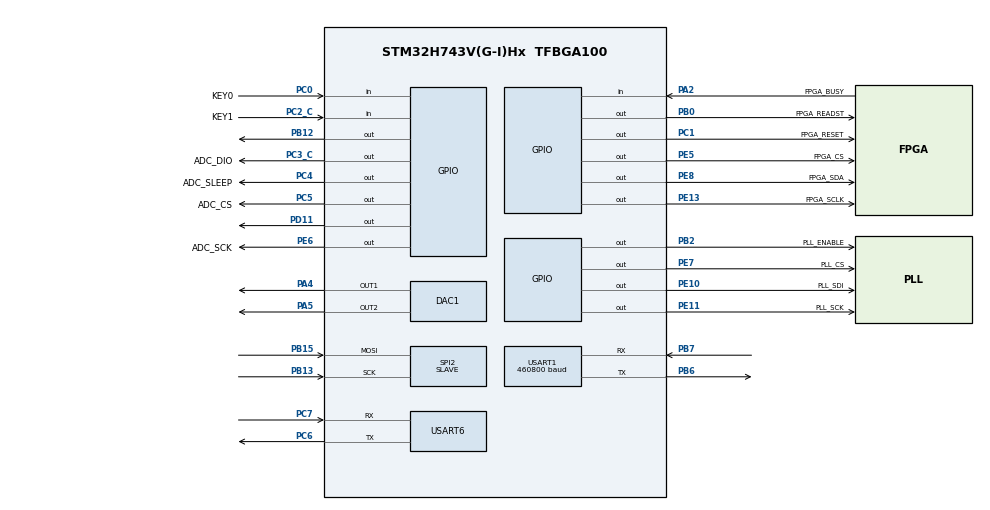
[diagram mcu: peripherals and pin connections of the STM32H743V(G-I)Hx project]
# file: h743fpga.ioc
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CORTEX_M7.CPU_ICache=Enabled
DAC1.DAC_Channel-DAC_OUT1=DAC_CHANNEL_1
DAC1.DAC_Channel-DAC_OUT2=DAC_CHANNEL_2
Dma.Request0=SPI2_RX
Dma.SPI2_RX.0.Direction=DMA_PERIPH_TO_MEMORY
Dma.SPI2_RX.0.EventEnable=DISABLE
Dma.SPI2_RX.0.FIFOMode=DMA_FIFOMODE_DISABLE
Dma.SPI2_RX.0.Instance=DMA1_Stream0
Dma.SPI2_RX.0.MemDataAlignment=DMA_MDATAALIGN_HALFWORD
Dma.SPI2_RX.0.MemInc=DMA_MINC_ENABLE
Dma.SPI2_RX.0.Mode=DMA_CIRCULAR
Dma.SPI2_RX.0.PeriphDataAlignment=DMA_PDATAALIGN_HALFWORD
Dma.SPI2_RX.0.PeriphInc=DMA_PINC_DISABLE
Dma.SPI2_RX.0.Polarity=HAL_DMAMUX_REQ_GEN_RISING
Dma.SPI2_RX.0.Priority=DMA_PRIORITY_LOW
Dma.SPI2_RX.0.RequestNumber=1
Dma.SPI2_RX.0.SignalID=NONE
Dma.SPI2_RX.0.SyncEnable=DISABLE
Dma.SPI2_RX.0.SyncPolarity=HAL_DMAMUX_SYNC_NO_EVENT
Dma.SPI2_RX.0.SyncRequestNumber=1
Dma.SPI2_RX.0.SyncSignalID=NONE
Mcu.Family=STM32H7
Mcu.Name=STM32H743V(G-I)Hx
Mcu.Package=TFBGA100
NVIC.DMA1_Stream0_IRQn=true\:0\:0\:false\:false\:true\:false\:true\:true
NVIC.PriorityGroup=NVIC_PRIORITYGROUP_4
NVIC.SPI2_IRQn=true\:0\:0\:false\:false\:true\:true\:true\:true
NVIC.TIM2_IRQn=true\:0\:0\:false\:false\:true\:true\:true\:true
NVIC.TIM6_DAC_IRQn=true\:0\:0\:false\:false\:true\:true\:true\:true
NVIC.TIM7_IRQn=true\:0\:0\:false\:false\:true\:true\:true\:true
NVIC.USART1_IRQn=true\:0\:0\:false\:false\:true\:true\:true\:true
NVIC.USART6_IRQn=true\:0\:0\:false\:false\:true\:true\:true\:true
PA13\ (JTMS/SWDIO).Mode=JTAG_5_pins
PA13\ (JTMS/SWDIO).Signal=DEBUG_JTMS-SWDIO
PA14\ (JTCK/SWCLK).Mode=JTAG_5_pins
PA14\ (JTCK/SWCLK).Signal=DEBUG_JTCK-SWCLK
PA15\ (JTDI).Mode=JTAG_5_pins
PA15\ (JTDI).Signal=DEBUG_JTDI
PA2.GPIO_Label=FPGA_BUSY
PA2.Signal=GPIO_Input
PA4.Signal=COMP_DAC11_group
PA5.Signal=COMP_DAC12_group
PB0.GPIO_Label=FPGA_READST
PB0.GPIO_Speed=GPIO_SPEED_FREQ_HIGH
PB0.PinState=GPIO_PIN_RESET
PB0.Signal=GPIO_Output
PB12.GPIO_Speed=GPIO_SPEED_FREQ_HIGH
PB12.PinState=GPIO_PIN_SET
PB12.Signal=GPIO_Output
PB13.GPIO_Speed=GPIO_SPEED_FREQ_VERY_HIGH
PB13.Mode=RX_Only_Simplex_Unidirect_Slave
PB13.Signal=SPI2_SCK
PB15.GPIO_Speed=GPIO_SPEED_FREQ_VERY_HIGH
PB15.Mode=RX_Only_Simplex_Unidirect_Slave
PB15.Signal=SPI2_MOSI
PB2.GPIO_Label=PLL_ENABLE
PB2.GPIO_Speed=GPIO_SPEED_FREQ_LOW
PB2.Signal=GPIO_Output
PB3\ (JTDO/TRACESWO).Mode=JTAG_5_pins
PB3\ (JTDO/TRACESWO).Signal=DEBUG_JTDO-SWO
PB4\ (NJTRST).Mode=JTAG_5_pins
PB4\ (NJTRST).Signal=DEBUG_JTRST
PB6.Mode=Asynchronous
PB6.Signal=USART1_TX
PB7.Mode=Asynchronous
PB7.Signal=USART1_RX
PC0.GPIO_Label=KEY0
PC0.Signal=GPIO_Input
PC1.GPIO_Label=FPGA_RESET
PC1.GPIO_Speed=GPIO_SPEED_FREQ_HIGH
PC1.PinState=GPIO_PIN_SET
PC1.Signal=GPIO_Output
PC2_C.GPIO_Label=KEY1
PC2_C.GPIO_PuPd=GPIO_PULLUP
PC2_C.Signal=GPIO_Input
PC3_C.GPIO_Label=ADC_DIO
PC3_C.GPIO_ModeDefaultOutputPP=GPIO_MODE_OUTPUT_PP
PC3_C.GPIO_PuPd=GPIO_PULLUP
PC3_C.GPIO_Speed=GPIO_SPEED_FREQ_LOW
PC3_C.PinState=GPIO_PIN_RESET
PC3_C.Signal=GPIO_Output
PC4.GPIO_Label=ADC_SLEEP
PC4.GPIO_Speed=GPIO_SPEED_FREQ_LOW
PC4.Signal=GPIO_Output
PC5.GPIO_Label=ADC_CS
PC5.GPIO_Speed=GPIO_SPEED_FREQ_LOW
PC5.PinState=GPIO_PIN_SET
PC5.Signal=GPIO_Output
PC6.Mode=Asynchronous
PC6.Signal=USART6_TX
PC7.Mode=Asynchronous
PC7.Signal=USART6_RX
PD11.Signal=GPIO_Output
PE10.GPIO_Label=PLL_SDI
PE10.GPIO_ModeDefaultOutputPP=GPIO_MODE_OUTPUT_PP
PE10.GPIO_PuPd=GPIO_PULLUP
PE10.GPIO_Speed=GPIO_SPEED_FREQ_LOW
PE10.PinState=GPIO_PIN_RESET
PE10.Signal=GPIO_Output
PE11.GPIO_Label=PLL_SCK
PE11.GPIO_Speed=GPIO_SPEED_FREQ_LOW
PE11.Signal=GPIO_Output
PE13.GPIO_Label=FPGA_SCLK
PE13.Signal=GPIO_Output
PE5.GPIO_Label=FPGA_CS
PE5.GPIO_Speed=GPIO_SPEED_FREQ_HIGH
PE5.PinState=GPIO_PIN_SET
PE5.Signal=GPIO_Output
PE6.GPIO_Label=ADC_SCK
PE6.GPIO_Speed=GPIO_SPEED_FREQ_LOW
PE6.Signal=GPIO_Output
PE7.GPIO_Label=PLL_CS
PE7.GPIO_Speed=GPIO_SPEED_FREQ_LOW
PE7.PinState=GPIO_PIN_RESET
PE7.Signal=GPIO_Output
PE8.GPIO_Label=FPGA_SDA
PE8.Signal=GPIO_Output
PE9.Signal=S_TIM1_CH1
PH0-OSC_IN\ (PH0).Mode=HSE-External-Oscillator
PH0-OSC_IN\ (PH0).Signal=RCC_OSC_IN
PH1-OSC_OUT\ (PH1).Mode=HSE-External-Oscillator
PH1-OSC_OUT\ (PH1).Signal=RCC_OSC_OUT
ProjectManager.HeapSize=0x200
ProjectManager.StackSize=0x400
ProjectManager.TargetToolchain=Makefile
RCC.ADCFreq_Value=100000000
RCC.APB1Freq_Value=100000000
RCC.APB2Freq_Value=100000000
RCC.APB3Freq_Value=100000000
RCC.APB4Freq_Value=100000000
RCC.CortexFreq_Value=400000000
RCC.D1PPRE=RCC_APB3_DIV2
RCC.D2PPRE1=RCC_APB1_DIV2
RCC.D2PPRE2=RCC_APB2_DIV2
RCC.D3PPRE=RCC_APB4_DIV2
RCC.DIVM1=2
RCC.DIVM2=4
RCC.DIVN1=64
RCC.DIVN2=80
RCC.DIVP2=5
RCC.HCLKFreq_Value=200000000
RCC.HPRE=RCC_HCLK_DIV2
RCC.PLLFRACN=0
RCC.PLLSourceVirtual=RCC_PLLSOURCE_HSE
RCC.SPI123CLockSelection=RCC_SPI123CLKSOURCE_PLL2
RCC.SYSCLKFreq_VALUE=400000000
RCC.SYSCLKSource=RCC_SYSCLKSOURCE_PLLCLK
RCC.USBFreq_Value=400000000
SH.COMP_DAC11_group.0=DAC1_OUT1,DAC_OUT1
SH.COMP_DAC12_group.0=DAC1_OUT2,DAC_OUT2
SH.S_TIM1_CH1.0=TIM1_CH1
SPI2.CLKPhase=SPI_PHASE_2EDGE
SPI2.CLKPolarity=SPI_POLARITY_HIGH
SPI2.DataSize=SPI_DATASIZE_16BIT
SPI2.Direction=SPI_DIRECTION_2LINES_RXONLY
SPI2.Mode=SPI_MODE_SLAVE
SPI2.VirtualType=VM_SLAVE
TIM7.Prescaler=999
USART1.BaudRate=460800
USART1.VirtualMode-Asynchronous=VM_ASYNC
USART6.VirtualMode=VM_ASYNC
VP_TIM2_VS_ClockSourceINT.Mode=Internal
VP_TIM7_VS_ClockSourceINT.Mode=Enable_Timer
board=custom

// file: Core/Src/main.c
/* USER CODE BEGIN Header */
/**
  ******************************************************************************
  * @file           : main.c
  * @brief          : Main program body
  ******************************************************************************
  * @attention
  *
  * Copyright (c) 2023 STMicroelectronics.
  * All rights reserved.
  *
  * This software is licensed under terms that can be found in the LICENSE file
  * in the root directory of this software component.
  * If no LICENSE file comes with this software, it is provided AS-IS.
  *
  ******************************************************************************
  */
/* USER CODE END Header */
#include "main.h"
#include "dac.h"
#include "dma.h"
#include "spi.h"
#include "tim.h"
#include "usart.h"
#include "gpio.h"

/* USER CODE BEGIN Includes */
#include "led.h"
#include "app.h"
/* USER CODE END Includes */

void SystemClock_Config(void);

int main(void)
{

  /* Enable I-Cache---------------------------------------------------------*/
  SCB_EnableICache();

  /* MCU Configuration--------------------------------------------------------*/

  /* Reset of all peripherals, Initializes the Flash interface and the Systick. */
  HAL_Init();

  /* Configure the system clock */
  SystemClock_Config();

  /* Initialize all configured peripherals */
  MX_GPIO_Init();
  MX_DMA_Init();
  MX_USART1_UART_Init();
  MX_SPI2_Init();
  MX_TIM2_Init();
  MX_DAC1_Init();
  MX_TIM7_Init();
  MX_USART6_UART_Init();
  /* USER CODE BEGIN 2 */
  LED_Init();
  APP_Init();
  /* USER CODE END 2 */

  /* Infinite loop */
  while (1)
  {

    /* USER CODE BEGIN 3 */
    APP_Loop();
  }
  /* USER CODE END 3 */
}

void SystemClock_Config(void)
{
  RCC_OscInitTypeDef RCC_OscInitStruct = {0};
  RCC_ClkInitTypeDef RCC_ClkInitStruct = {0};

  /** Supply configuration update enable
  */
  HAL_PWREx_ConfigSupply(PWR_LDO_SUPPLY);

  /** Configure the main internal regulator output voltage
  */
  __HAL_PWR_VOLTAGESCALING_CONFIG(PWR_REGULATOR_VOLTAGE_SCALE1);

  while(!__HAL_PWR_GET_FLAG(PWR_FLAG_VOSRDY)) {}

  /** Initializes the RCC Oscillators according to the specified parameters
  * in the RCC_OscInitTypeDef structure.
  */
  RCC_OscInitStruct.OscillatorType = RCC_OSCILLATORTYPE_HSE;
  RCC_OscInitStruct.HSEState = RCC_HSE_ON;
  RCC_OscInitStruct.PLL.PLLState = RCC_PLL_ON;
  RCC_OscInitStruct.PLL.PLLSource = RCC_PLLSOURCE_HSE;
  RCC_OscInitStruct.PLL.PLLM = 2;
  RCC_OscInitStruct.PLL.PLLN = 64;
  RCC_OscInitStruct.PLL.PLLP = 2;
  RCC_OscInitStruct.PLL.PLLQ = 2;
  RCC_OscInitStruct.PLL.PLLR = 2;
  RCC_OscInitStruct.PLL.PLLRGE = RCC_PLL1VCIRANGE_3;
  RCC_OscInitStruct.PLL.PLLVCOSEL = RCC_PLL1VCOWIDE;
  RCC_OscInitStruct.PLL.PLLFRACN = 0;
  if (HAL_RCC_OscConfig(&RCC_OscInitStruct) != HAL_OK)
  {
    Error_Handler();
  }

  /** Initializes the CPU, AHB and APB buses clocks
  */
  RCC_ClkInitStruct.ClockType = RCC_CLOCKTYPE_HCLK|RCC_CLOCKTYPE_SYSCLK
                              |RCC_CLOCKTYPE_PCLK1|RCC_CLOCKTYPE_PCLK2
                              |RCC_CLOCKTYPE_D3PCLK1|RCC_CLOCKTYPE_D1PCLK1;
  RCC_ClkInitStruct.SYSCLKSource = RCC_SYSCLKSOURCE_PLLCLK;
  RCC_ClkInitStruct.SYSCLKDivider = RCC_SYSCLK_DIV1;
  RCC_ClkInitStruct.AHBCLKDivider = RCC_HCLK_DIV2;
  RCC_ClkInitStruct.APB3CLKDivider = RCC_APB3_DIV2;
  RCC_ClkInitStruct.APB1CLKDivider = RCC_APB1_DIV2;
  RCC_ClkInitStruct.APB2CLKDivider = RCC_APB2_DIV2;
  RCC_ClkInitStruct.APB4CLKDivider = RCC_APB4_DIV2;

  if (HAL_RCC_ClockConfig(&RCC_ClkInitStruct, FLASH_LATENCY_2) != HAL_OK)
  {
    Error_Handler();
  }
}

void Error_Handler(void)
{
  __disable_irq();
  while (1)
  {
  }
}
